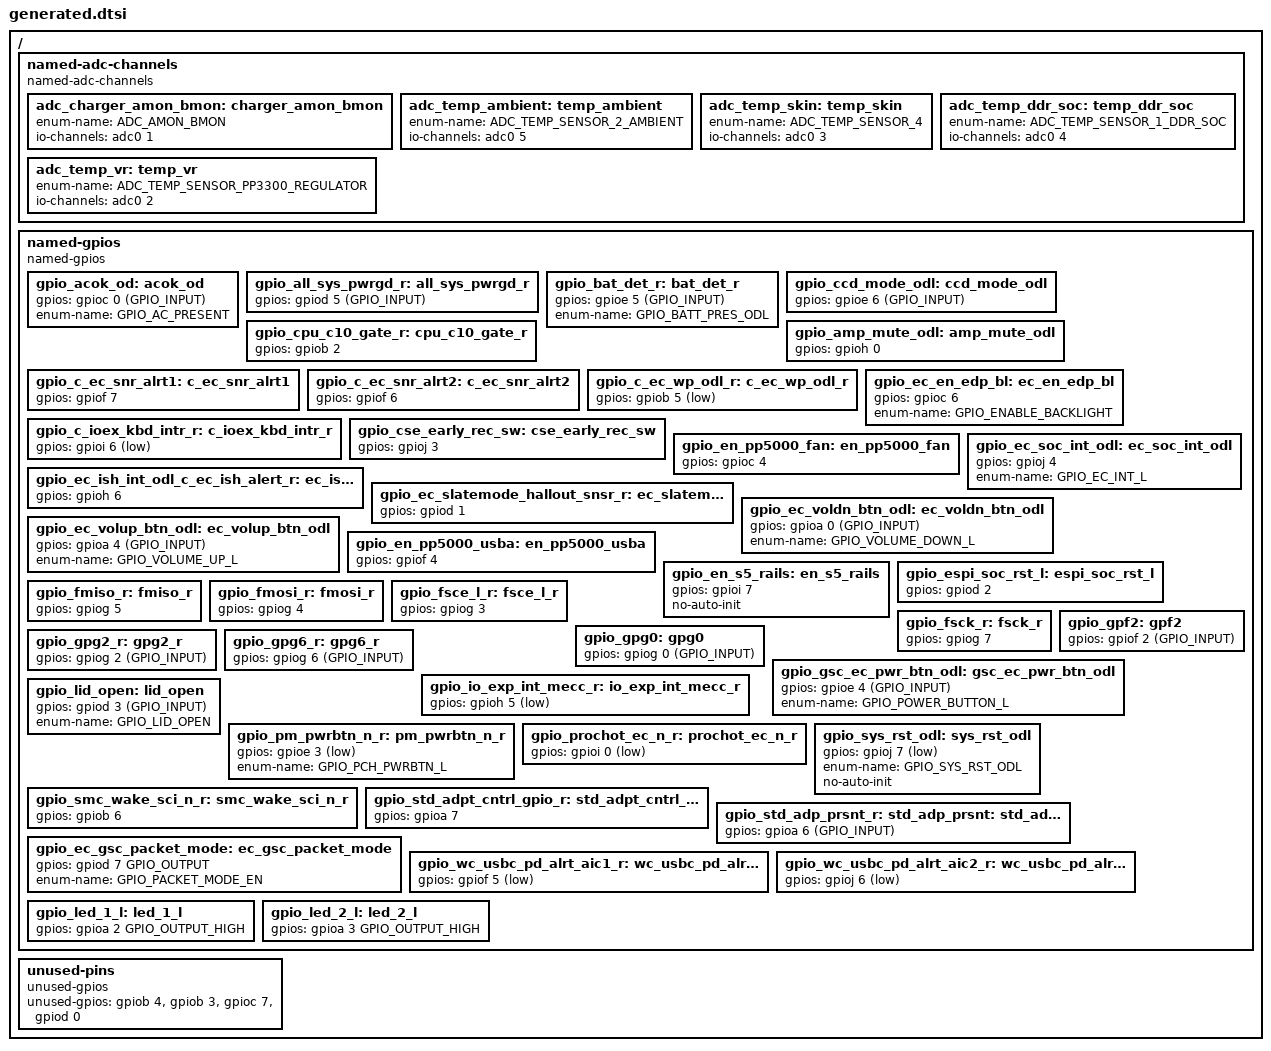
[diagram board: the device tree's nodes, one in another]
/* Copyright 2025 The ChromiumOS Authors
 * Use of this source code is governed by a BSD-style license that can be
 * found in the LICENSE file.
 *
 * This file was auto-generated but contains manual edits
 */

/ {

	named-adc-channels {
		compatible = "named-adc-channels";

		adc_charger_amon_bmon: charger_amon_bmon {
			enum-name = "ADC_AMON_BMON";
			io-channels = <&adc0 1>;
		};
		adc_temp_ambient: temp_ambient {
			enum-name = "ADC_TEMP_SENSOR_2_AMBIENT";
			io-channels = <&adc0 5>;
		};
		adc_temp_skin: temp_skin {
			enum-name = "ADC_TEMP_SENSOR_4";
			io-channels = <&adc0 3>;
		};
		adc_temp_vr: temp_vr {
			enum-name = "ADC_TEMP_SENSOR_PP3300_REGULATOR";
			io-channels = <&adc0 2>;
		};
		adc_temp_ddr_soc: temp_ddr_soc {
			enum-name = "ADC_TEMP_SENSOR_1_DDR_SOC";
			io-channels = <&adc0 4>;
		};
	};

	named-gpios {
		compatible = "named-gpios";

		gpio_acok_od: acok_od {
			// signal name was manually overriden from "bga_pine5"
			gpios = <&gpioc 0 (GPIO_INPUT)>;
			enum-name = "GPIO_AC_PRESENT";
		};
		gpio_all_sys_pwrgd_r: all_sys_pwrgd_r {
			gpios = <&gpiod 5 (GPIO_INPUT)>;
		};
		gpio_bat_det_r: bat_det_r {
			gpios = <&gpioe 5 (GPIO_INPUT)>;
			enum-name = "GPIO_BATT_PRES_ODL";
		};
		gpio_ccd_mode_odl: ccd_mode_odl {
			// signal name was manually overriden from "bga_pinm1"
			gpios = <&gpioe 6 (GPIO_INPUT)>;
		};
		gpio_cpu_c10_gate_r: cpu_c10_gate_r {
			gpios = <&gpiob 2 (GPIO_INPUT | GPIO_VOLTAGE_1P8)>;
		};
		gpio_amp_mute_odl: amp_mute_odl {
			gpios = <&gpioh 0 (GPIO_OUTPUT_LOW | GPIO_OPEN_DRAIN)>;
		};
		gpio_c_ec_snr_alrt1: c_ec_snr_alrt1 {
			// signal name was manually overriden from "bga_pinc1"
			gpios = <&gpiof 7 (GPIO_INPUT | GPIO_VOLTAGE_1P8)>;
		};
		gpio_c_ec_snr_alrt2: c_ec_snr_alrt2 {
			// signal name was manually overriden from "bga_pinb1"
			gpios = <&gpiof 6 (GPIO_INPUT | GPIO_VOLTAGE_1P8)>;
		};
		gpio_c_ec_wp_odl_r: c_ec_wp_odl_r {
			gpios = <&gpiob 5 (GPIO_INPUT | GPIO_ACTIVE_LOW)>;
		};
		gpio_ec_en_edp_bl: ec_en_edp_bl {
			gpios = <&gpioc 6 (GPIO_OUTPUT | GPIO_ACTIVE_HIGH | GPIO_OUTPUT_INIT_HIGH)>;
			enum-name = "GPIO_ENABLE_BACKLIGHT";
		};
		gpio_c_ioex_kbd_intr_r: c_ioex_kbd_intr_r {
			gpios = <&gpioi 6 (GPIO_INPUT | GPIO_ACTIVE_LOW)>;
		};
		gpio_cse_early_rec_sw: cse_early_rec_sw {
			gpios = <&gpioj 3 (GPIO_OUTPUT | GPIO_OPEN_DRAIN | GPIO_ACTIVE_HIGH | GPIO_OUTPUT_INIT_LOW)>;
		};
		gpio_en_pp5000_fan: en_pp5000_fan {
			gpios = <&gpioc 4 (GPIO_OUTPUT | GPIO_ACTIVE_HIGH | GPIO_OUTPUT_INIT_LOW)>;
		};
		gpio_ec_ish_int_odl_c_ec_ish_alert_r: ec_ish_int_odl_c_ec_ish_alert_r {
			gpios = <&gpioh 6 (GPIO_INPUT | GPIO_VOLTAGE_1P8)>;
		};
		gpio_ec_slatemode_hallout_snsr_r: ec_slatemode_hallout_snsr_r {
			gpios = <&gpiod 1 (GPIO_INPUT | GPIO_VOLTAGE_1P8)>;
		};
		gpio_ec_soc_int_odl: ec_soc_int_odl {
			gpios = <&gpioj 4 (GPIO_OUTPUT | GPIO_OPEN_DRAIN | GPIO_ACTIVE_HIGH | GPIO_OUTPUT_INIT_HIGH)>;
			enum-name = "GPIO_EC_INT_L";
		};
		gpio_ec_voldn_btn_odl: ec_voldn_btn_odl {
			// signal name was manually overriden from "vol_dn_ec_r"
			gpios = <&gpioa 0 (GPIO_INPUT)>;
			enum-name = "GPIO_VOLUME_DOWN_L";
		};
		gpio_ec_volup_btn_odl: ec_volup_btn_odl {
			// signal name was manually overriden from "volume_up_r"
			gpios = <&gpioa 4 (GPIO_INPUT)>;
			enum-name = "GPIO_VOLUME_UP_L";
		};
		gpio_en_pp5000_usba: en_pp5000_usba {
			// signal name was manually overriden from "c_en_pp5000_typea_r"
			gpios = <&gpiof 4 (GPIO_OUTPUT | GPIO_ACTIVE_HIGH)>;
		};
		/* Power sequencing signal needed by temp sensor driver */
		gpio_en_s5_rails: en_s5_rails {
			gpios = <&gpioi 7 (GPIO_OUTPUT | GPIO_ACTIVE_HIGH | GPIO_OUTPUT_INIT_LOW)>;
			no-auto-init;
		};
		gpio_espi_soc_rst_l: espi_soc_rst_l {
			gpios = <&gpiod 2 (GPIO_INPUT | GPIO_VOLTAGE_1P8)>;
		};
		gpio_fmiso_r: fmiso_r {
			gpios = <&gpiog 5 (GPIO_INPUT | GPIO_PULL_UP)>;
		};
		gpio_fmosi_r: fmosi_r {
			gpios = <&gpiog 4 (GPIO_INPUT | GPIO_PULL_DOWN)>;
		};
		gpio_fsce_l_r: fsce_l_r {
			gpios = <&gpiog 3 (GPIO_INPUT | GPIO_PULL_UP)>;
		};
		gpio_fsck_r: fsck_r {
			gpios = <&gpiog 7 (GPIO_INPUT | GPIO_PULL_DOWN)>;
		};
		gpio_gpf2: gpf2 {
			// signal name was manually overriden from "bga_pina10"
			gpios = <&gpiof 2 (GPIO_INPUT)>;
		};
		gpio_gpg0: gpg0 {
			gpios = <&gpiog 0 (GPIO_INPUT)>;
		};
		gpio_gpg2_r: gpg2_r {
			gpios = <&gpiog 2 (GPIO_INPUT)>;
		};
		gpio_gpg6_r: gpg6_r {
			gpios = <&gpiog 6 (GPIO_INPUT)>;
		};
		gpio_gsc_ec_pwr_btn_odl: gsc_ec_pwr_btn_odl {
			// signal name was manually overriden from "bga_pinb4"
			gpios = <&gpioe 4 (GPIO_INPUT)>;
			enum-name = "GPIO_POWER_BUTTON_L";
		};
		gpio_io_exp_int_mecc_r: io_exp_int_mecc_r {
			gpios = <&gpioh 5 (GPIO_INPUT | GPIO_ACTIVE_LOW)>;
		};
		gpio_lid_open: lid_open {
			gpios = <&gpiod 3 (GPIO_INPUT)>;
			enum-name = "GPIO_LID_OPEN";
		};
		gpio_pm_pwrbtn_n_r: pm_pwrbtn_n_r {
			gpios = <&gpioe 3 (GPIO_OUTPUT | GPIO_OPEN_DRAIN | GPIO_ACTIVE_LOW)>;
			enum-name = "GPIO_PCH_PWRBTN_L";
		};
		gpio_prochot_ec_n_r: prochot_ec_n_r {
			gpios = <&gpioi 0 (GPIO_INPUT | GPIO_ACTIVE_LOW)>;
		};
		gpio_sys_rst_odl: sys_rst_odl {
			gpios = <&gpioj 7 (GPIO_OUTPUT | GPIO_OPEN_DRAIN | GPIO_ACTIVE_LOW | GPIO_OUTPUT_INIT_HIGH)>;
			enum-name = "GPIO_SYS_RST_ODL";
			no-auto-init;
		};
		gpio_smc_wake_sci_n_r: smc_wake_sci_n_r {
			gpios = <&gpiob 6 (GPIO_OUTPUT | GPIO_OPEN_DRAIN | GPIO_ACTIVE_HIGH | GPIO_OUTPUT_INIT_HIGH)>;
		};
		gpio_std_adpt_cntrl_gpio_r: std_adpt_cntrl_gpio_r {
			gpios = <&gpioa 7 (GPIO_OUTPUT | GPIO_ACTIVE_HIGH)>;
		};
		gpio_std_adp_prsnt_r: std_adp_prsnt: std_adp_prsnt_r {
			gpios = <&gpioa 6 (GPIO_INPUT)>;
		};
		gpio_ec_gsc_packet_mode: ec_gsc_packet_mode {
			gpios = <&gpiod 7 GPIO_OUTPUT>;
			enum-name = "GPIO_PACKET_MODE_EN";
		};
		gpio_wc_usbc_pd_alrt_aic1_r: wc_usbc_pd_alrt_aic1_r {
			gpios = <&gpiof 5 (GPIO_INPUT | GPIO_ACTIVE_LOW)>;
		};
		gpio_wc_usbc_pd_alrt_aic2_r: wc_usbc_pd_alrt_aic2_r {
			gpios = <&gpioj 6 (GPIO_INPUT | GPIO_ACTIVE_LOW)>;
		};
		gpio_led_1_l: led_1_l {
			gpios = <&gpioa 2 GPIO_OUTPUT_HIGH>;
		};
		gpio_led_2_l: led_2_l {
			gpios = <&gpioa 3 GPIO_OUTPUT_HIGH>;
		};
	};

	unused-pins {
		compatible = "unused-gpios";
		unused-gpios =
			/* BGA_PINA2 - unused 1.8V I2C bus - pull down to avoid
			 * voltage level issues if this AIC is connected to a
			 * different base RVP board */
			<&gpiob 4 (GPIO_INPUT | GPIO_PULL_DOWN)>,
			/* BGA_PINA5 - unused 1.8V I2C bus - pull down to avoid
			 * voltage level issues if this AIC is connected to a
			 * different base RVP board */
			<&gpiob 3 (GPIO_INPUT | GPIO_PULL_DOWN)>,
			/* BGA_PINM2 */
			<&gpioc 7 (GPIO_INPUT | GPIO_PULL_UP)>,
			/* BGA_PINN1 */
			<&gpiod 0 (GPIO_INPUT | GPIO_PULL_UP)>;
	};
};
